# ioADuCM4050 register map
Registers from a debugger description file.
Registers are 16-bit, access not given, no defined reset value unless marked. A register's access mark holds for its fields unless they carry their own. Addresses are absolute; registers are grouped by the start of their names; lines under a group give offsets from that group; [hi:lo] are bit positions; {n}, {i} and the like mark numbered series; 'fields as' and 'values as' point back to an identical list; <NAME> marks a mode.

## TMR0
0x40000000 TMR0_LOAD
0x40000004 TMR0_CURCNT
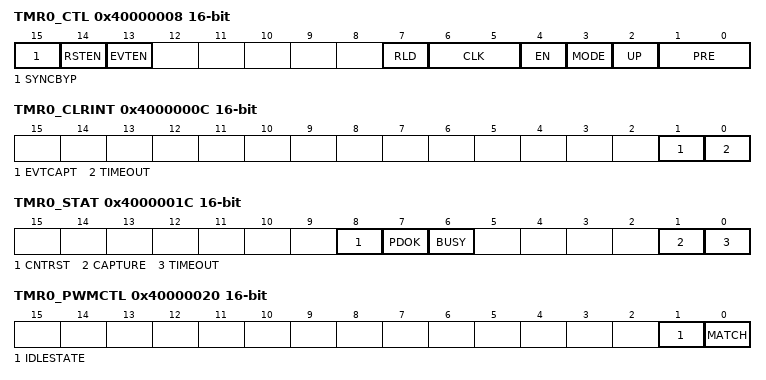
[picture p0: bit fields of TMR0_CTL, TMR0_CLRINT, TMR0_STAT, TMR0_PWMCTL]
0x40000008 TMR0_CTL
  [15] SYNCBYP, [14] RSTEN, [13] EVTEN, [7] RLD, [6:5] CLK, [4] EN, [3] MODE, [2] UP, [1:0] PRE
0x4000000C TMR0_CLRINT
  [1] EVTCAPT, [0] TIMEOUT
0x40000010 TMR0_CAPTURE
0x40000014 TMR0_ALOAD
0x40000018 TMR0_ACURCNT
0x4000001C TMR0_STAT
  [8] CNTRST, [7] PDOK, [6] BUSY, [1] CAPTURE, [0] TIMEOUT
0x40000020 TMR0_PWMCTL
  [1] IDLESTATE, [0] MATCH
0x40000024 TMR0_PWMMATCH
0x40000028 TMR0_EVENTSELECT
  [5:0] EVTRANGE

## TMR1
0x40000400 TMR1_LOAD
0x40000404 TMR1_CURCNT
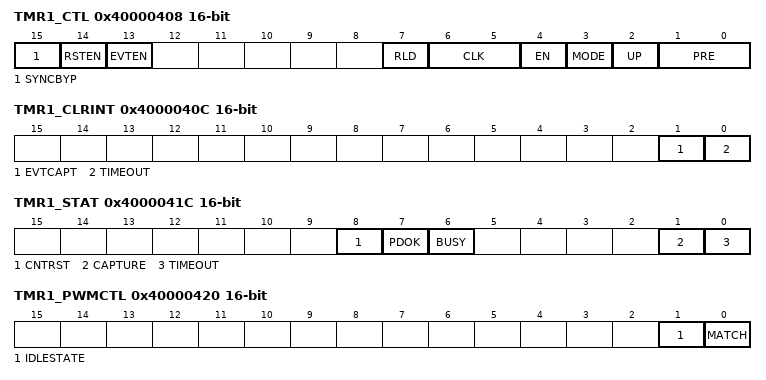
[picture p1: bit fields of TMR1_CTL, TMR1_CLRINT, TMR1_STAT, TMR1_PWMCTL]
0x40000408 TMR1_CTL
  [15] SYNCBYP, [14] RSTEN, [13] EVTEN, [7] RLD, [6:5] CLK, [4] EN, [3] MODE, [2] UP, [1:0] PRE
0x4000040C TMR1_CLRINT
  [1] EVTCAPT, [0] TIMEOUT
0x40000410 TMR1_CAPTURE
0x40000414 TMR1_ALOAD
0x40000418 TMR1_ACURCNT
0x4000041C TMR1_STAT
  [8] CNTRST, [7] PDOK, [6] BUSY, [1] CAPTURE, [0] TIMEOUT
0x40000420 TMR1_PWMCTL
  [1] IDLESTATE, [0] MATCH
0x40000424 TMR1_PWMMATCH
0x40000428 TMR1_EVENTSELECT
  [5:0] EVTRANGE

## TMR2
0x40000800 TMR2_LOAD
0x40000804 TMR2_CURCNT
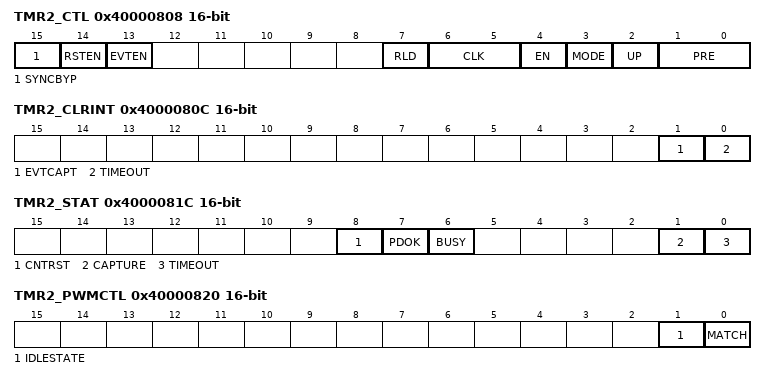
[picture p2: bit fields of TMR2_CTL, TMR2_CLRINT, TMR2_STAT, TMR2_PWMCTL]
0x40000808 TMR2_CTL
  [15] SYNCBYP, [14] RSTEN, [13] EVTEN, [7] RLD, [6:5] CLK, [4] EN, [3] MODE, [2] UP, [1:0] PRE
0x4000080C TMR2_CLRINT
  [1] EVTCAPT, [0] TIMEOUT
0x40000810 TMR2_CAPTURE
0x40000814 TMR2_ALOAD
0x40000818 TMR2_ACURCNT
0x4000081C TMR2_STAT
  [8] CNTRST, [7] PDOK, [6] BUSY, [1] CAPTURE, [0] TIMEOUT
0x40000820 TMR2_PWMCTL
  [1] IDLESTATE, [0] MATCH
0x40000824 TMR2_PWMMATCH
0x40000828 TMR2_EVENTSELECT
  [5:0] EVTRANGE

## TMR
0x40000C00 TMR_RGB_LOAD
0x40000C04 TMR_RGB_CURCNT
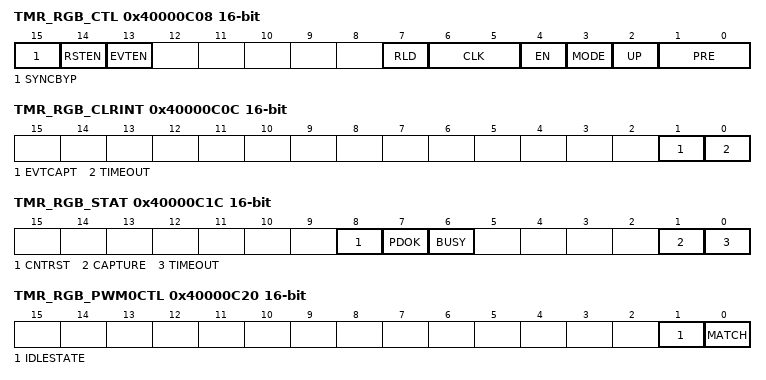
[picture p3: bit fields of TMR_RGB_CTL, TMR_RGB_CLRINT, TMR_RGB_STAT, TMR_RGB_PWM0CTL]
0x40000C08 TMR_RGB_CTL
  [15] SYNCBYP, [14] RSTEN, [13] EVTEN, [7] RLD, [6:5] CLK, [4] EN, [3] MODE, [2] UP, [1:0] PRE
0x40000C0C TMR_RGB_CLRINT
  [1] EVTCAPT, [0] TIMEOUT
0x40000C10 TMR_RGB_CAPTURE
0x40000C14 TMR_RGB_ALOAD
0x40000C18 TMR_RGB_ACURCNT
0x40000C1C TMR_RGB_STAT
  [8] CNTRST, [7] PDOK, [6] BUSY, [1] CAPTURE, [0] TIMEOUT
0x40000C20 TMR_RGB_PWM0CTL
  [1] IDLESTATE, [0] MATCH
0x40000C24 TMR_RGB_PWM0MATCH
0x40000C28 TMR_RGB_EVENTSELECT
  [5:0] EVTRANGE
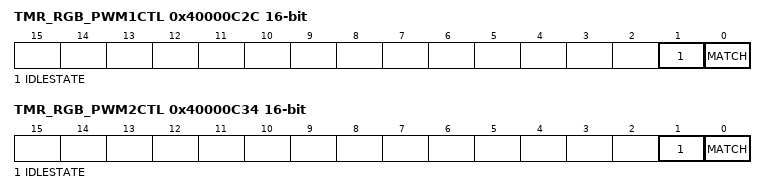
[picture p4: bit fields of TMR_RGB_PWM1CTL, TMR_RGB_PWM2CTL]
0x40000C2C TMR_RGB_PWM1CTL
  [1] IDLESTATE, [0] MATCH
0x40000C30 TMR_RGB_PWM1MATCH
0x40000C34 TMR_RGB_PWM2CTL
  [1] IDLESTATE, [0] MATCH
0x40000C38 TMR_RGB_PWM2MATCH

## SYS
0x40002020 SYS_ADIID
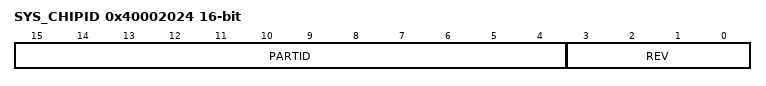
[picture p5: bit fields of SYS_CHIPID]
0x40002024 SYS_CHIPID
  [15:4] PARTID, [3:0] REV
0x40002040 SYS_SWDEN

## WDT0
0x40002C00 WDT0_LOAD
0x40002C04 WDT0_CCNT
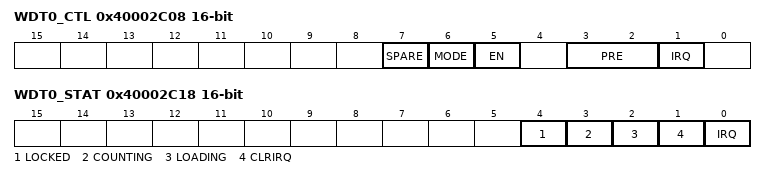
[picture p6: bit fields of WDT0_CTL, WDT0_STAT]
0x40002C08 WDT0_CTL
  [7] SPARE, [6] MODE, [5] EN, [3:2] PRE, [1] IRQ
0x40002C0C WDT0_RESTART
0x40002C18 WDT0_STAT
  [4] LOCKED, [3] COUNTING, [2] LOADING, [1] CLRIRQ, [0] IRQ

## I2C0
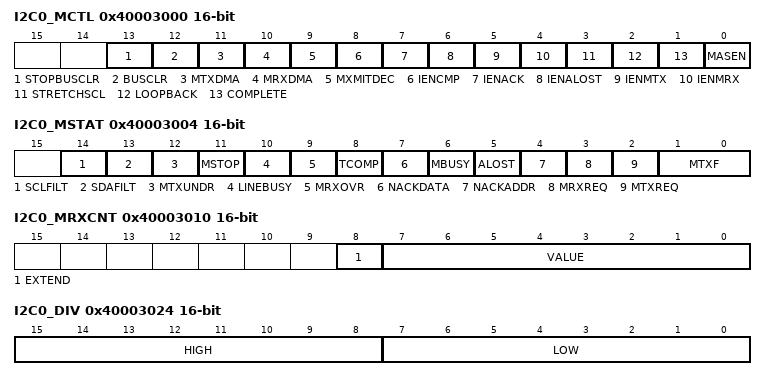
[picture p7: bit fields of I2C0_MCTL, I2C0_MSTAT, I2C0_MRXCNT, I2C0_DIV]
0x40003000 I2C0_MCTL
  [13] STOPBUSCLR, [12] BUSCLR, [11] MTXDMA, [10] MRXDMA, [9] MXMITDEC, [8] IENCMP, [7] IENACK, [6] IENALOST, [5] IENMTX, [4] IENMRX, [3] STRETCHSCL, [2] LOOPBACK, [1] COMPLETE, [0] MASEN
0x40003004 I2C0_MSTAT
  [14] SCLFILT, [13] SDAFILT, [12] MTXUNDR, [11] MSTOP, [10] LINEBUSY, [9] MRXOVR, [8] TCOMP, [7] NACKDATA, [6] MBUSY, [5] ALOST, [4] NACKADDR, [3] MRXREQ, [2] MTXREQ, [1:0] MTXF
0x40003008 I2C0_MRX
  [7:0] VALUE
0x4000300C I2C0_MTX
  [7:0] VALUE
0x40003010 I2C0_MRXCNT
  [8] EXTEND, [7:0] VALUE
0x40003014 I2C0_MCRXCNT
  [7:0] VALUE
0x40003018 I2C0_ADDR1
  [7:0] VALUE
0x4000301C I2C0_ADDR2
  [7:0] VALUE
0x40003020 I2C0_BYT
  [7:0] SBYTE
0x40003024 I2C0_DIV
  [15:8] HIGH, [7:0] LOW
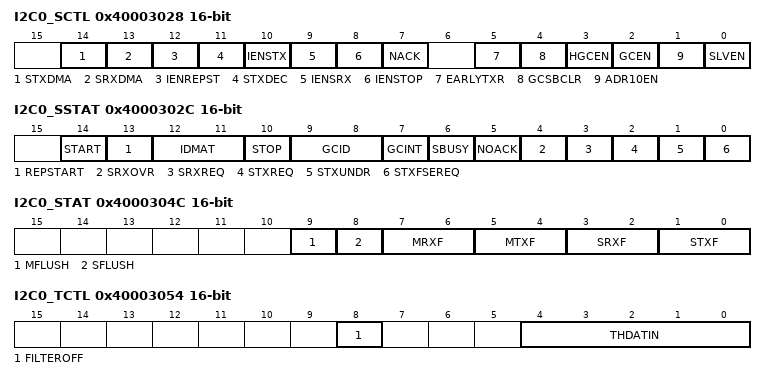
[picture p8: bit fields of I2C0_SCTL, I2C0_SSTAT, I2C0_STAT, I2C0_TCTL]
0x40003028 I2C0_SCTL
  [14] STXDMA, [13] SRXDMA, [12] IENREPST, [11] STXDEC, [10] IENSTX, [9] IENSRX, [8] IENSTOP, [7] NACK, [5] EARLYTXR, [4] GCSBCLR, [3] HGCEN, [2] GCEN, [1] ADR10EN, [0] SLVEN
0x4000302C I2C0_SSTAT
  [14] START, [13] REPSTART, [12:11] IDMAT, [10] STOP, [9:8] GCID, [7] GCINT, [6] SBUSY, [5] NOACK, [4] SRXOVR, [3] SRXREQ, [2] STXREQ, [1] STXUNDR, [0] STXFSEREQ
0x40003030 I2C0_SRX
  [7:0] VALUE
0x40003034 I2C0_STX
  [7:0] VALUE
0x40003038 I2C0_ALT
  [7:0] ID
{0x4000303C+4i} I2C0_ID{i} (i=0..3)
  [7:0] VALUE
0x4000304C I2C0_STAT
  [9] MFLUSH, [8] SFLUSH, [7:6] MRXF, [5:4] MTXF, [3:2] SRXF, [1:0] STXF
0x40003050 I2C0_SHCTL
  [0] RST
0x40003054 I2C0_TCTL
  [8] FILTEROFF, [4:0] THDATIN
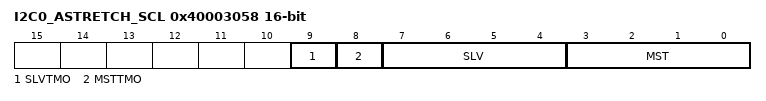
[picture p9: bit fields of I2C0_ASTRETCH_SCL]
0x40003058 I2C0_ASTRETCH_SCL
  [9] SLVTMO, [8] MSTTMO, [7:4] SLV, [3:0] MST

## Notices in the file
Copyright (c) 2014-2017 Analog Devices, Inc.  All Rights Reserved.
This software is proprietary and confidential to Analog Devices, Inc. and
its licensors.
